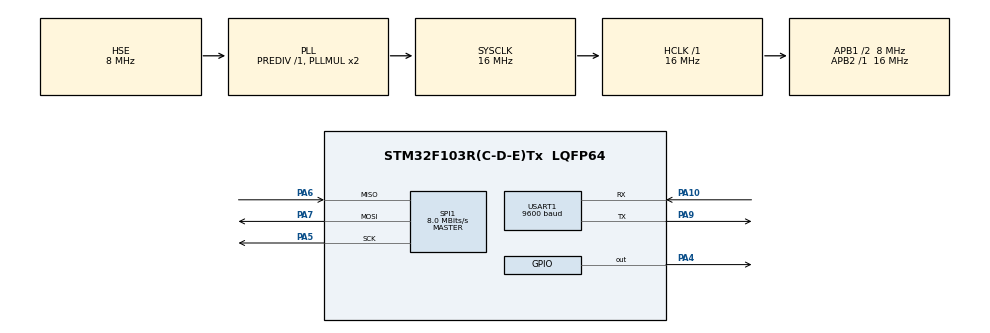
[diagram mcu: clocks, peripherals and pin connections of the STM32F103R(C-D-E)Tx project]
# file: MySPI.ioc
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Dma.Request0=SPI1_RX
Dma.Request1=SPI1_TX
Dma.SPI1_RX.0.Direction=DMA_PERIPH_TO_MEMORY
Dma.SPI1_RX.0.Instance=DMA1_Channel2
Dma.SPI1_RX.0.MemDataAlignment=DMA_MDATAALIGN_HALFWORD
Dma.SPI1_RX.0.MemInc=DMA_MINC_ENABLE
Dma.SPI1_RX.0.Mode=DMA_NORMAL
Dma.SPI1_RX.0.PeriphDataAlignment=DMA_PDATAALIGN_HALFWORD
Dma.SPI1_RX.0.PeriphInc=DMA_PINC_DISABLE
Dma.SPI1_RX.0.Priority=DMA_PRIORITY_LOW
Dma.SPI1_TX.1.Direction=DMA_MEMORY_TO_PERIPH
Dma.SPI1_TX.1.Instance=DMA1_Channel3
Dma.SPI1_TX.1.MemDataAlignment=DMA_MDATAALIGN_HALFWORD
Dma.SPI1_TX.1.MemInc=DMA_MINC_ENABLE
Dma.SPI1_TX.1.Mode=DMA_NORMAL
Dma.SPI1_TX.1.PeriphDataAlignment=DMA_PDATAALIGN_HALFWORD
Dma.SPI1_TX.1.PeriphInc=DMA_PINC_DISABLE
Dma.SPI1_TX.1.Priority=DMA_PRIORITY_LOW
Mcu.Family=STM32F1
Mcu.Name=STM32F103R(C-D-E)Tx
Mcu.Package=LQFP64
NVIC.DMA1_Channel2_IRQn=true\:0\:0\:false\:false\:true\:false\:true
NVIC.DMA1_Channel3_IRQn=true\:0\:0\:false\:false\:true\:false\:true
NVIC.PriorityGroup=NVIC_PRIORITYGROUP_4
NVIC.USART1_IRQn=true\:0\:0\:false\:false\:true\:true\:true
PA10.Mode=Asynchronous
PA10.Signal=USART1_RX
PA4.Signal=GPIO_Output
PA5.Mode=Full_Duplex_Master
PA5.Signal=SPI1_SCK
PA6.Mode=Full_Duplex_Master
PA6.Signal=SPI1_MISO
PA7.Mode=Full_Duplex_Master
PA7.Signal=SPI1_MOSI
PA9.Mode=Asynchronous
PA9.Signal=USART1_TX
PD0-OSC_IN.Mode=HSE-External-Oscillator
PD0-OSC_IN.Signal=RCC_OSC_IN
PD1-OSC_OUT.Mode=HSE-External-Oscillator
PD1-OSC_OUT.Signal=RCC_OSC_OUT
ProjectManager.HeapSize=0x200
ProjectManager.StackSize=0x400
ProjectManager.TargetToolchain=MDK-ARM V5.27
RCC.AHBFreq_Value=16000000
RCC.APB1CLKDivider=RCC_HCLK_DIV2
RCC.APB1Freq_Value=8000000
RCC.APB1TimFreq_Value=16000000
RCC.APB2Freq_Value=16000000
RCC.APB2TimFreq_Value=16000000
RCC.HCLKFreq_Value=16000000
RCC.PLLSourceVirtual=RCC_PLLSOURCE_HSE
RCC.SYSCLKFreq_VALUE=16000000
RCC.SYSCLKSource=RCC_SYSCLKSOURCE_PLLCLK
RCC.USBFreq_Value=16000000
SPI1.CalculateBaudRate=8.0 MBits/s
SPI1.DataSize=SPI_DATASIZE_16BIT
SPI1.Direction=SPI_DIRECTION_2LINES
SPI1.Mode=SPI_MODE_MASTER
SPI1.VirtualType=VM_MASTER
USART1.BaudRate=9600
USART1.VirtualMode=VM_ASYNC
VP_SYS_VS_ND.Mode=No_Debug
board=custom

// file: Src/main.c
/* USER CODE BEGIN Header */
/**
  ******************************************************************************
  * @file           : main.c
  * @brief          : Main program body
  ******************************************************************************
  * @attention
  *
  * <h2><center>&copy; Copyright (c) 2020 STMicroelectronics.
  * All rights reserved.</center></h2>
  *
  * This software component is licensed by ST under BSD 3-Clause license,
  * the "License"; You may not use this file except in compliance with the
  * License. You may obtain a copy of the License at:
  *                        opensource.org/licenses/BSD-3-Clause
  *
  ******************************************************************************
  */
/* USER CODE END Header */

#include "main.h"
#include "dma.h"
#include "spi.h"
#include "usart.h"
#include "gpio.h"

/* USER CODE BEGIN Includes */
#include "myspi.h"
#include "stdio.h"
#include "math.h"
/* USER CODE END Includes */

void SystemClock_Config(void);

int main(void)
{
  /* USER CODE BEGIN 1 */
  uint16_t num = 0xbbaa;
//  uint8_t n=0xee;
  /* USER CODE END 1 */

  /* MCU Configuration--------------------------------------------------------*/

  /* Reset of all peripherals, Initializes the Flash interface and the Systick. */
  HAL_Init();

  /* Configure the system clock */
  SystemClock_Config();

  /* Initialize all configured peripherals */
  MX_GPIO_Init();
  MX_DMA_Init();
  MX_SPI1_Init();
  MX_USART1_UART_Init();

  /* Infinite loop */
  /* USER CODE BEGIN WHILE */
  while (1)
  {
		//HAL_UART_Transmit(&huart1,(uint8_t *)&num,1,1000);
		num=ADS1118_GetData(1);
		HAL_Delay(1000);
		printf("(double)num==%lf\r\n",(double)num);
		printf("%lf v\r\n\r\n",(double)num/pow(2,15)*2.964);
//    num = 88;
//		//printf("%d\r\n",num);

//		printf("v=%d\r\n",num);
//    n=(uint8_t)(num>>8);
//    printf("%d\n",n);
//    //HAL_UART_Transmit(&huart1,&n,sizeof(n),1000);
//    n=(uint8_t)(num);
//    printf("%d\n",n);
//    //HAL_UART_Transmit(&huart1,&n,sizeof(n),1000);
 //   HAL_Delay(400);

    /* USER CODE END WHILE */

  }
}

void SystemClock_Config(void)
{
  RCC_OscInitTypeDef RCC_OscInitStruct = {0};
  RCC_ClkInitTypeDef RCC_ClkInitStruct = {0};

  /** Initializes the CPU, AHB and APB busses clocks
  */
  RCC_OscInitStruct.OscillatorType = RCC_OSCILLATORTYPE_HSE;
  RCC_OscInitStruct.HSEState = RCC_HSE_ON;
  RCC_OscInitStruct.HSEPredivValue = RCC_HSE_PREDIV_DIV1;
  RCC_OscInitStruct.HSIState = RCC_HSI_ON;
  RCC_OscInitStruct.PLL.PLLState = RCC_PLL_ON;
  RCC_OscInitStruct.PLL.PLLSource = RCC_PLLSOURCE_HSE;
  RCC_OscInitStruct.PLL.PLLMUL = RCC_PLL_MUL2;
  if (HAL_RCC_OscConfig(&RCC_OscInitStruct) != HAL_OK)
  {
    Error_Handler();
  }
  /** Initializes the CPU, AHB and APB busses clocks
  */
  RCC_ClkInitStruct.ClockType = RCC_CLOCKTYPE_HCLK|RCC_CLOCKTYPE_SYSCLK
                              |RCC_CLOCKTYPE_PCLK1|RCC_CLOCKTYPE_PCLK2;
  RCC_ClkInitStruct.SYSCLKSource = RCC_SYSCLKSOURCE_PLLCLK;
  RCC_ClkInitStruct.AHBCLKDivider = RCC_SYSCLK_DIV1;
  RCC_ClkInitStruct.APB1CLKDivider = RCC_HCLK_DIV2;
  RCC_ClkInitStruct.APB2CLKDivider = RCC_HCLK_DIV1;

  if (HAL_RCC_ClockConfig(&RCC_ClkInitStruct, FLASH_LATENCY_0) != HAL_OK)
  {
    Error_Handler();
  }
}

void Error_Handler(void)
{
}

/************************ (C) COPYRIGHT STMicroelectronics *****END OF FILE****/
